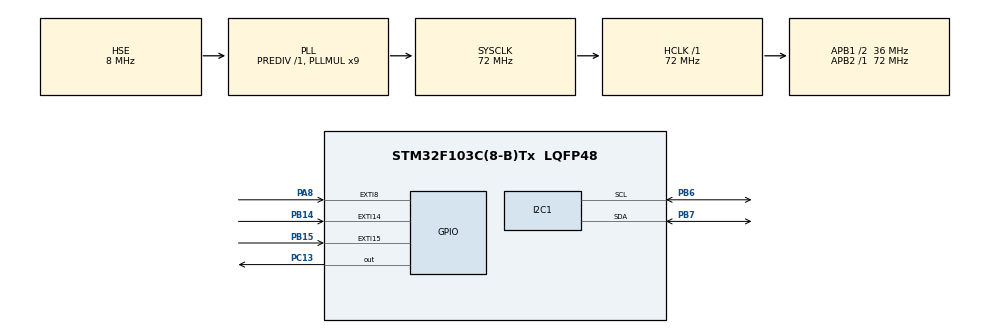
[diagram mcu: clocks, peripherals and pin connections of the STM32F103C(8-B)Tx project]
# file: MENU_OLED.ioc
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Mcu.Family=STM32F1
RCC.PLLSourceVirtual=RCC_PLLSOURCE_HSE
PD1-OSC_OUT.Mode=HSE-External-Oscillator
PC13-TAMPER-RTC.Signal=GPIO_Output
NVIC.TIM1_UP_IRQn=true\:0\:0\:false\:false\:true\:true\:true
PD0-OSC_IN.Signal=RCC_OSC_IN
RCC.APB1CLKDivider=RCC_HCLK_DIV2
PB15.Signal=GPXTI15
RCC.SYSCLKSource=RCC_SYSCLKSOURCE_PLLCLK
ProjectManager.StackSize=0x400
PD1-OSC_OUT.Signal=RCC_OSC_OUT
PA13.Signal=SYS_JTMS-SWDIO
TIM1.AutoReloadPreload=TIM_AUTORELOAD_PRELOAD_ENABLE
TIM1.Prescaler=6400
ProjectManager.TargetToolchain=STM32CubeIDE
I2C1.I2C_Mode=I2C_Fast
RCC.HCLKFreq_Value=72000000
RCC.APB2TimFreq_Value=72000000
PB6.Signal=I2C1_SCL
PB6.Mode=I2C
RCC.USBFreq_Value=72000000
RCC.AHBFreq_Value=72000000
PD0-OSC_IN.Mode=HSE-External-Oscillator
NVIC.EXTI15_10_IRQn=true\:0\:0\:false\:false\:true\:true\:true
PB14.Signal=GPXTI14
board=custom
RCC.PLLMUL=RCC_PLL_MUL9
TIM1.TIM_MasterOutputTrigger=TIM_TRGO_ENABLE
RCC.APB2Freq_Value=72000000
PA14.Mode=Serial_Wire
PB7.Signal=I2C1_SDA
PA8.Signal=GPXTI8
PA13.Mode=Serial_Wire
Mcu.Name=STM32F103C(8-B)Tx
VP_TIM1_VS_ClockSourceINT.Mode=Internal
RCC.SYSCLKFreq_VALUE=72000000
Mcu.Package=LQFP48
PB14.GPIO_PuPd=GPIO_PULLUP
PB15.GPIO_PuPd=GPIO_PULLUP
PB7.Mode=I2C
NVIC.EXTI9_5_IRQn=true\:0\:0\:false\:false\:true\:true\:true
PA14.Signal=SYS_JTCK-SWCLK
ProjectManager.HeapSize=0x200
PA8.GPIO_PuPd=GPIO_PULLUP
NVIC.PriorityGroup=NVIC_PRIORITYGROUP_4
RCC.APB1TimFreq_Value=72000000
TIM1.Period=100
RCC.APB1Freq_Value=36000000

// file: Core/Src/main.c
/* USER CODE BEGIN Header */
/**
  ******************************************************************************
  * @file           : main.c
  * @brief          : Main program body
  ******************************************************************************
  * @attention
  *
  * <h2><center>&copy; Copyright (c) 2021 STMicroelectronics.
  * All rights reserved.</center></h2>
  *
  * This software component is licensed by ST under BSD 3-Clause license,
  * the "License"; You may not use this file except in compliance with the
  * License. You may obtain a copy of the License at:
  *                        opensource.org/licenses/BSD-3-Clause
  *
  ******************************************************************************
  */
/* USER CODE END Header */
#include "main.h"

/* USER CODE BEGIN Includes */
#include <oled/fonts.h>
#include <oled/oled_ssd1306.h>
#include <oled/ssd1306.h>
#include <oled/oled_main.h>

#include <menu/oled_simulation_menu.h>
/* USER CODE END Includes */

I2C_HandleTypeDef hi2c1;

TIM_HandleTypeDef htim1;

void SystemClock_Config(void);
static void MX_GPIO_Init(void);
static void MX_I2C1_Init(void);
static void MX_TIM1_Init(void);

int main(void)
{

  /* MCU Configuration--------------------------------------------------------*/

  /* Reset of all peripherals, Initializes the Flash interface and the Systick. */
  HAL_Init();

  /* Configure the system clock */
  SystemClock_Config();

  /* Initialize all configured peripherals */
  MX_GPIO_Init();
  MX_I2C1_Init();
  MX_TIM1_Init();
  /* USER CODE BEGIN 2 */
  HAL_GPIO_WritePin(GPIOC, GPIO_PIN_13, GPIO_PIN_SET);

  // OLED init
  ssd1306_Init();
  ssd1306_Fill(Black);
  ssd1306_UpdateScreen();
  /* USER CODE END 2 */

  /* Infinite loop */
  /* USER CODE BEGIN WHILE */
  while (1)
  {
	  menu();

    /* USER CODE END WHILE */

  }
}

void SystemClock_Config(void)
{
  RCC_OscInitTypeDef RCC_OscInitStruct = {0};
  RCC_ClkInitTypeDef RCC_ClkInitStruct = {0};

  /** Initializes the RCC Oscillators according to the specified parameters
  * in the RCC_OscInitTypeDef structure.
  */
  RCC_OscInitStruct.OscillatorType = RCC_OSCILLATORTYPE_HSE;
  RCC_OscInitStruct.HSEState = RCC_HSE_ON;
  RCC_OscInitStruct.HSEPredivValue = RCC_HSE_PREDIV_DIV1;
  RCC_OscInitStruct.HSIState = RCC_HSI_ON;
  RCC_OscInitStruct.PLL.PLLState = RCC_PLL_ON;
  RCC_OscInitStruct.PLL.PLLSource = RCC_PLLSOURCE_HSE;
  RCC_OscInitStruct.PLL.PLLMUL = RCC_PLL_MUL9;
  if (HAL_RCC_OscConfig(&RCC_OscInitStruct) != HAL_OK)
  {
    Error_Handler();
  }
  /** Initializes the CPU, AHB and APB buses clocks
  */
  RCC_ClkInitStruct.ClockType = RCC_CLOCKTYPE_HCLK|RCC_CLOCKTYPE_SYSCLK
                              |RCC_CLOCKTYPE_PCLK1|RCC_CLOCKTYPE_PCLK2;
  RCC_ClkInitStruct.SYSCLKSource = RCC_SYSCLKSOURCE_PLLCLK;
  RCC_ClkInitStruct.AHBCLKDivider = RCC_SYSCLK_DIV1;
  RCC_ClkInitStruct.APB1CLKDivider = RCC_HCLK_DIV2;
  RCC_ClkInitStruct.APB2CLKDivider = RCC_HCLK_DIV1;

  if (HAL_RCC_ClockConfig(&RCC_ClkInitStruct, FLASH_LATENCY_2) != HAL_OK)
  {
    Error_Handler();
  }
}

static void MX_I2C1_Init(void)
{

  hi2c1.Instance = I2C1;
  hi2c1.Init.ClockSpeed = 400000;
  hi2c1.Init.DutyCycle = I2C_DUTYCYCLE_2;
  hi2c1.Init.OwnAddress1 = 0;
  hi2c1.Init.AddressingMode = I2C_ADDRESSINGMODE_7BIT;
  hi2c1.Init.DualAddressMode = I2C_DUALADDRESS_DISABLE;
  hi2c1.Init.OwnAddress2 = 0;
  hi2c1.Init.GeneralCallMode = I2C_GENERALCALL_DISABLE;
  hi2c1.Init.NoStretchMode = I2C_NOSTRETCH_DISABLE;
  if (HAL_I2C_Init(&hi2c1) != HAL_OK)
  {
    Error_Handler();
  }

}

static void MX_TIM1_Init(void)
{

  TIM_ClockConfigTypeDef sClockSourceConfig = {0};
  TIM_MasterConfigTypeDef sMasterConfig = {0};

  htim1.Instance = TIM1;
  htim1.Init.Prescaler = 6400;
  htim1.Init.CounterMode = TIM_COUNTERMODE_UP;
  htim1.Init.Period = 100;
  htim1.Init.ClockDivision = TIM_CLOCKDIVISION_DIV1;
  htim1.Init.RepetitionCounter = 0;
  htim1.Init.AutoReloadPreload = TIM_AUTORELOAD_PRELOAD_ENABLE;
  if (HAL_TIM_Base_Init(&htim1) != HAL_OK)
  {
    Error_Handler();
  }
  sClockSourceConfig.ClockSource = TIM_CLOCKSOURCE_INTERNAL;
  if (HAL_TIM_ConfigClockSource(&htim1, &sClockSourceConfig) != HAL_OK)
  {
    Error_Handler();
  }
  sMasterConfig.MasterOutputTrigger = TIM_TRGO_ENABLE;
  sMasterConfig.MasterSlaveMode = TIM_MASTERSLAVEMODE_DISABLE;
  if (HAL_TIMEx_MasterConfigSynchronization(&htim1, &sMasterConfig) != HAL_OK)
  {
    Error_Handler();
  }

}

static void MX_GPIO_Init(void)
{
  GPIO_InitTypeDef GPIO_InitStruct = {0};

  /* GPIO Ports Clock Enable */
  __HAL_RCC_GPIOC_CLK_ENABLE();
  __HAL_RCC_GPIOD_CLK_ENABLE();
  __HAL_RCC_GPIOB_CLK_ENABLE();
  __HAL_RCC_GPIOA_CLK_ENABLE();

  /*Configure GPIO pin Output Level */
  HAL_GPIO_WritePin(GPIOC, GPIO_PIN_13, GPIO_PIN_RESET);

  /*Configure GPIO pin : PC13 */
  GPIO_InitStruct.Pin = GPIO_PIN_13;
  GPIO_InitStruct.Mode = GPIO_MODE_OUTPUT_PP;
  GPIO_InitStruct.Pull = GPIO_NOPULL;
  GPIO_InitStruct.Speed = GPIO_SPEED_FREQ_LOW;
  HAL_GPIO_Init(GPIOC, &GPIO_InitStruct);

  /*Configure GPIO pins : PB14 PB15 */
  GPIO_InitStruct.Pin = GPIO_PIN_14|GPIO_PIN_15;
  GPIO_InitStruct.Mode = GPIO_MODE_IT_RISING;
  GPIO_InitStruct.Pull = GPIO_PULLUP;
  HAL_GPIO_Init(GPIOB, &GPIO_InitStruct);

  /*Configure GPIO pin : PA8 */
  GPIO_InitStruct.Pin = GPIO_PIN_8;
  GPIO_InitStruct.Mode = GPIO_MODE_IT_RISING;
  GPIO_InitStruct.Pull = GPIO_PULLUP;
  HAL_GPIO_Init(GPIOA, &GPIO_InitStruct);

  /* EXTI interrupt init*/
  HAL_NVIC_SetPriority(EXTI9_5_IRQn, 0, 0);
  HAL_NVIC_EnableIRQ(EXTI9_5_IRQn);

  HAL_NVIC_SetPriority(EXTI15_10_IRQn, 0, 0);
  HAL_NVIC_EnableIRQ(EXTI15_10_IRQn);

}

void Error_Handler(void)
{
  __disable_irq();
  while (1)
  {
  }
}

/************************ (C) COPYRIGHT STMicroelectronics *****END OF FILE****/
